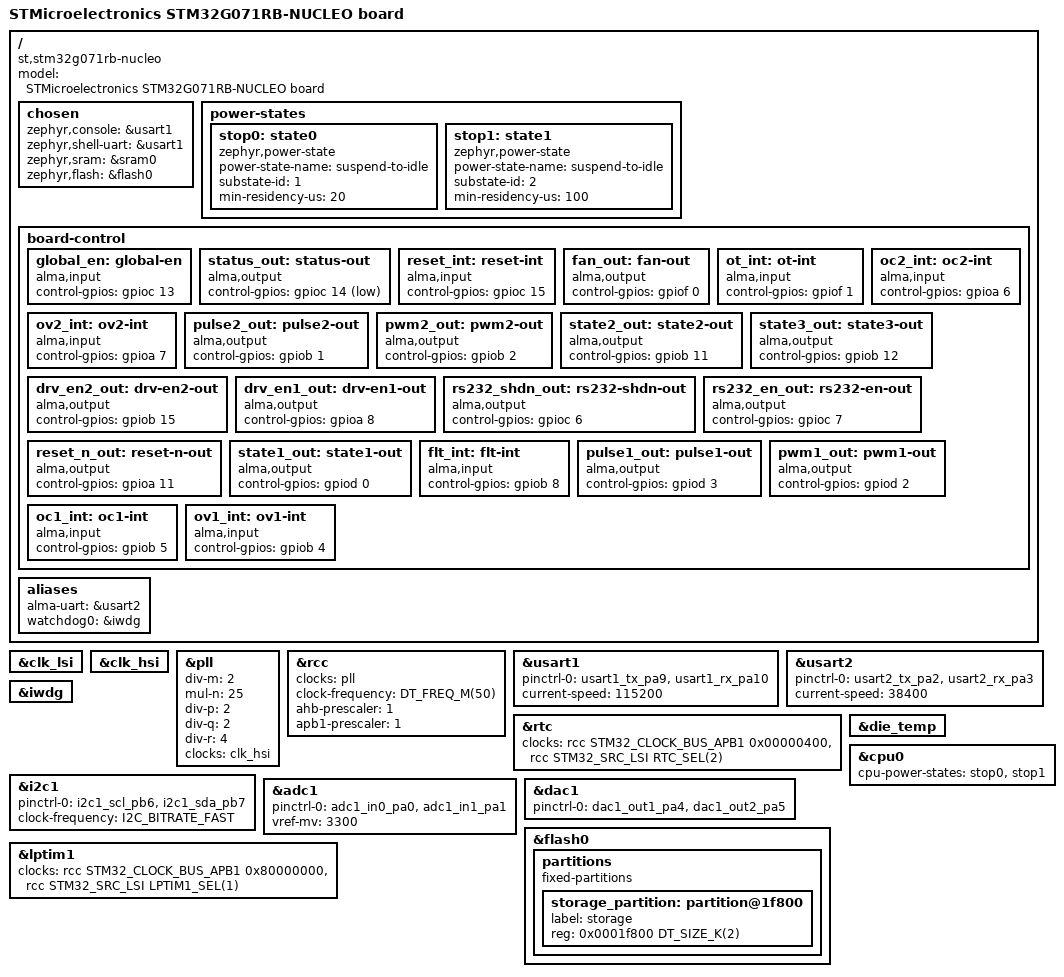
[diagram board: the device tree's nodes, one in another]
/*
 * Copyright (c) 2023 Marin Jurjević <marin.jurjevic@hotmail.com>
 *
 * SPDX-License-Identifier: Apache-2.0
 */

/dts-v1/;
#include <st/g0/stm32g071Xb.dtsi>
#include <st/g0/stm32g071r(6-8-b)tx-pinctrl.dtsi>
#include "arduino_r3_connector.dtsi"

/ {
	model = "STMicroelectronics STM32G071RB-NUCLEO board";
	compatible = "st,stm32g071rb-nucleo";

	chosen {
		zephyr,console = &usart1;
		zephyr,shell-uart = &usart1;
		zephyr,sram = &sram0;
		zephyr,flash = &flash0;
	};

	power-states {
		stop0: state0 {
			compatible = "zephyr,power-state";
			power-state-name = "suspend-to-idle";
			substate-id = <1>;
			min-residency-us = <20>;
		};
		stop1: state1 {
			compatible = "zephyr,power-state";
			power-state-name = "suspend-to-idle";
			substate-id = <2>;
			min-residency-us = <100>;
		};
	};

	board-control {
		global_en: global-en {
			compatible = "alma,input";
			control-gpios = <&gpioc 13 GPIO_ACTIVE_HIGH>;
			status = "okay";
		};
		status_out: status-out {
			compatible = "alma,output";
			control-gpios = <&gpioc 14 GPIO_ACTIVE_LOW>;
			status = "okay";
		};
		reset_int: reset-int {
			compatible = "alma,input";
			control-gpios = <&gpioc 15 GPIO_ACTIVE_HIGH>;
			status = "okay";
		};
		fan_out: fan-out {
			compatible = "alma,output";
			control-gpios = <&gpiof 0 GPIO_ACTIVE_HIGH>;
			status = "okay";
		};
		ot_int: ot-int {
			compatible = "alma,input";
			control-gpios = <&gpiof 1 GPIO_ACTIVE_HIGH>;
			status = "okay";
		};
		oc2_int: oc2-int {
			compatible = "alma,input";
			control-gpios = <&gpioa 6 GPIO_ACTIVE_HIGH>;
			status = "okay";
		};
		ov2_int: ov2-int {
			compatible = "alma,input";
			control-gpios = <&gpioa 7 GPIO_ACTIVE_HIGH>;
			status = "okay";
		};
		pulse2_out: pulse2-out {
			compatible = "alma,output";
			control-gpios = <&gpiob 1 GPIO_ACTIVE_HIGH>;
			status = "okay";
		};
		pwm2_out: pwm2-out {
			compatible = "alma,output";
			control-gpios = <&gpiob 2 GPIO_ACTIVE_HIGH>;
			status = "okay";
		};
		state2_out: state2-out {
			compatible = "alma,output";
			control-gpios = <&gpiob 11 GPIO_ACTIVE_HIGH>;
			status = "okay";
		};
		state3_out: state3-out {
			compatible = "alma,output";
			control-gpios = <&gpiob 12 GPIO_ACTIVE_HIGH>;
			status = "okay";
		};
		drv_en2_out: drv-en2-out {
			compatible = "alma,output";
			control-gpios = <&gpiob 15 GPIO_ACTIVE_HIGH>;
			status = "okay";
		};
		drv_en1_out: drv-en1-out {
			compatible = "alma,output";
			control-gpios = <&gpioa 8 GPIO_ACTIVE_HIGH>;
			status = "okay";
		};
		rs232_shdn_out: rs232-shdn-out {
			compatible = "alma,output";
			control-gpios = <&gpioc 6 GPIO_ACTIVE_HIGH>;
			status = "okay";
		};
		rs232_en_out: rs232-en-out {
			compatible = "alma,output";
			control-gpios = <&gpioc 7 GPIO_ACTIVE_HIGH>;
			status = "okay";
		};
		reset_n_out: reset-n-out {
			compatible = "alma,output";
			control-gpios = <&gpioa 11 GPIO_ACTIVE_HIGH>;
			status = "okay";
		};
		state1_out: state1-out {
			compatible = "alma,output";
			control-gpios = <&gpiod 0 GPIO_ACTIVE_HIGH>;
			status = "okay";
		};
		flt_int: flt-int {
			compatible = "alma,input";
			control-gpios = <&gpiob 8 GPIO_ACTIVE_HIGH>;
			status = "okay";
		};
		pulse1_out: pulse1-out {
			compatible = "alma,output";
			control-gpios = <&gpiod 3 GPIO_ACTIVE_HIGH>;
			status = "okay";
		};
		pwm1_out: pwm1-out {
			compatible = "alma,output";
			control-gpios = <&gpiod 2 GPIO_ACTIVE_HIGH>;
			status = "okay";
		};
		oc1_int: oc1-int {
			compatible = "alma,input";
			control-gpios = <&gpiob 5 GPIO_ACTIVE_HIGH>;
			status = "okay";
		};
		ov1_int: ov1-int {
			compatible = "alma,input";
			control-gpios = <&gpiob 4 GPIO_ACTIVE_HIGH>;
			status = "okay";
		};
	};

	aliases {
		alma-uart = &usart2;
		watchdog0 = &iwdg;
	};
};

&clk_lsi {
	status = "okay";
};

&clk_hsi {
	status = "okay";
};

&pll {
	div-m = <2>;
	mul-n = <25>;
	div-p = <2>;
	div-q = <2>;
	div-r = <4>;
	clocks = <&clk_hsi>;
	status = "okay";
};

&rcc {
	clocks = <&pll>;
	clock-frequency = <DT_FREQ_M(50)>;
	ahb-prescaler = <1>;
	apb1-prescaler = <1>;
};

&usart1 {
	pinctrl-0 = <&usart1_tx_pa9 &usart1_rx_pa10>;
	pinctrl-names = "default";
	current-speed = <115200>;
	status = "okay";
};

&usart2 {
	pinctrl-0 = <&usart2_tx_pa2 &usart2_rx_pa3>;
	pinctrl-names = "default";
	current-speed = <38400>;
	status = "okay";
};

&rtc {
	clocks = <&rcc STM32_CLOCK_BUS_APB1 0x00000400>,
	         <&rcc STM32_SRC_LSI RTC_SEL(2)>;
	status = "okay";
};

&iwdg {
	status = "okay";
};

&i2c1 {
	pinctrl-0 = <&i2c1_scl_pb6 &i2c1_sda_pb7>;
	pinctrl-names = "default";
	status = "okay";
	clock-frequency = <I2C_BITRATE_FAST>;
};

&adc1 {
	pinctrl-0 = <&adc1_in0_pa0 &adc1_in1_pa1>;
	pinctrl-names = "default";
	status = "okay";
	vref-mv = <3300>;
};

&dac1 {
	status = "okay";
	pinctrl-0 = <&dac1_out1_pa4 &dac1_out2_pa5>;
	pinctrl-names = "default";
};

&die_temp {
	status = "okay";
};

&flash0 {
	partitions {
		compatible = "fixed-partitions";
		#address-cells = <1>;
		#size-cells = <1>;

		/* Set 2KB of storage at the end of 128KB flash */
		storage_partition: partition@1f800 {
			label = "storage";
			reg = <0x0001f800 DT_SIZE_K(2)>;
		};
	};
};

&cpu0 {
	cpu-power-states = <&stop0 &stop1>;
};

&lptim1 {
	clocks = <&rcc STM32_CLOCK_BUS_APB1 0x80000000>,
	         <&rcc STM32_SRC_LSI LPTIM1_SEL(1)>;
	status = "okay";
};
